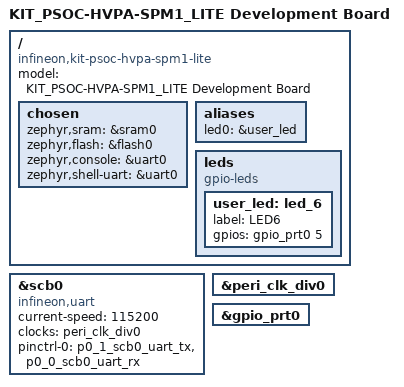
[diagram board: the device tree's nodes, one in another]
/*
 * SPDX-FileCopyrightText: Copyright (c) 2026 Infineon Technologies AG,
 * SPDX-FileCopyrightText: or an affiliate of Infineon Technologies AG. All rights reserved.
 *
 * SPDX-License-Identifier: Apache-2.0
 */

/dts-v1/;
#include <arm/infineon/psoc4/mpns/cy8c4147lde_hv734.dtsi>

#include "kit_psoc_hvpa_spm1_lite-pinctrl.dtsi"

/ {
	compatible = "infineon,kit-psoc-hvpa-spm1-lite", "infineon,psoc4hvpaspm10";
	model = "KIT_PSOC-HVPA-SPM1_LITE Development Board";

	chosen {
		zephyr,sram = &sram0;
		zephyr,flash = &flash0;
		zephyr,console = &uart0;
		zephyr,shell-uart = &uart0;
	};

	aliases {
		led0 = &user_led;
	};

	leds {
		compatible = "gpio-leds";

		user_led: led_6 {
			label = "LED6";
			gpios = <&gpio_prt0 5 GPIO_ACTIVE_HIGH>;
		};
	};
};

uart0: &scb0 {
	compatible = "infineon,uart";
	current-speed = <115200>;
	clocks = <&peri_clk_div0>;
	pinctrl-0 = <&p0_1_scb0_uart_tx &p0_0_scb0_uart_rx>;
	pinctrl-names = "default";
	status = "okay";
};

&peri_clk_div0 {
	status = "okay";
};

&gpio_prt0 {
	status = "okay";
};
